# DSS0_DISPC_0_COMMON_M register map
Vendor: Texas Instruments
Peripheral module from a debugger description file (folder J7ES).
Registers are 32-bit, access per field, reset 0x0 unless marked. A register's access mark holds for its fields unless they carry their own. Offsets are as the file gives them; lines under a group give offsets from that group; [hi:lo] are bit positions; {n}, {i} and the like mark numbered series; 'fields as' and 'values as' point back to an identical list; <NAME> marks a mode.

## DSS0_DISPC_0_COMMON_M
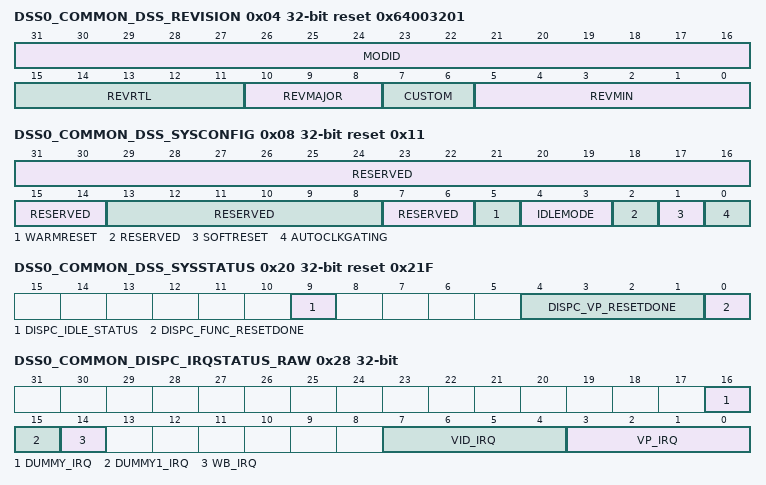
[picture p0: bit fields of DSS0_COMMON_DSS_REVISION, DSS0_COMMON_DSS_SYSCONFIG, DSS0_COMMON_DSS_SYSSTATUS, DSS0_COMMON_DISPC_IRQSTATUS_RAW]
0x04 DSS0_COMMON_DSS_REVISION ro reset 0x64003201 — This register contains the K3_DSS revision number
  [31:16] MODID — Module ID Field
  [15:11] REVRTL — RTL Revision
  [10:8] REVMAJOR — Major Revision
  [7:6] CUSTOM
  [5:0] REVMIN — Minor Revision
0x08 DSS0_COMMON_DSS_SYSCONFIG reset 0x11 — This register controls various parameters related to software reset and IP idle
  [31:14] RESERVED ro — Write 0's for future compatibility.
  [13:8] RESERVED ro — Write 0's for future compatibility.
  [7:6] RESERVED ro — Write 0's for future compatibility.
  [5] WARMRESET rw
  [4:3] IDLEMODE rw — Deprecated
  [2] RESERVED ro — Write 0's for future compatibility.
  [1] SOFTRESET rw — Software reset.
  [0] AUTOCLKGATING rw — Internal clock gating strategy
0x20 DSS0_COMMON_DSS_SYSSTATUS ro reset 0x21F — This register provides status information about the module, excluding the interrupt status information
  [9] DISPC_IDLE_STATUS — Idle status of DISPC
  [4:1] DISPC_VP_RESETDONE — Reset status of VP
  [0] DISPC_FUNC_RESETDONE — Reset status of DISPC Functional clock domain
0x28 DSS0_COMMON_DISPC_IRQSTATUS_RAW access not given — RAW Interrupt status. Raw status is set even if interrupt is not enabled. Write 1 to set the RAW status
  [16] DUMMY_IRQ — Dummy IRQ STATUS- Reserved for future use (access RW1S)
  [15] DUMMY1_IRQ — Dummy IRQ STATUS- Reserved for future use (access RW1S)
  [14] WB_IRQ — WB IRQ STATUS. (access RW1S)
  [7:4] VID_IRQ — VID IRQ STATUS. (access RW1S)
  [3:0] VP_IRQ — VP (access RW1S)
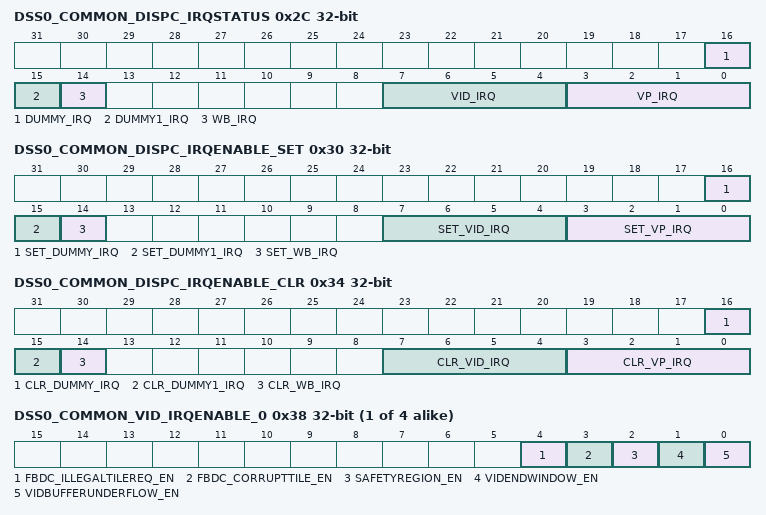
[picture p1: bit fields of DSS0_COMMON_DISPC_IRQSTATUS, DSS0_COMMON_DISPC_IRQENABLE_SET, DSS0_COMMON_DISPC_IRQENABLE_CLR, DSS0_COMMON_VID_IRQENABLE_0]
0x2C DSS0_COMMON_DISPC_IRQSTATUS access not given — Interrupt status. Enabled status, isn't set unless event is enabled. Write 1 to clear the status after interrupt has been serviced. RAW status also gets cleared, i.e. even if not enabled
  [16] DUMMY_IRQ — Dummy IRQ STATUS-Reserved for future use (access RW1C)
  [15] DUMMY1_IRQ — Dummy IRQ STATUS-Reserved for future use (access RW1C)
  [14] WB_IRQ — WB IRQ STATUS. (access RW1C)
  [7:4] VID_IRQ — VID IRQ STATUS. (access RW1C)
  [3:0] VP_IRQ — VP (access RW1C)
0x30 DSS0_COMMON_DISPC_IRQENABLE_SET access not given — SET Interrupt enable. Write 1 to set interrupt enable. Readout equal to corresponding _CLR register
  [16] SET_DUMMY_IRQ — Dummy IRQ (access RW1S)
  [15] SET_DUMMY1_IRQ — Dummy IRQ (access RW1S)
  [14] SET_WB_IRQ — WB IRQ, if WB pipeline is present (access RW1S)
  [7:4] SET_VID_IRQ — VID IRQ. (access RW1S)
  [3:0] SET_VP_IRQ — VP (access RW1S)
0x34 DSS0_COMMON_DISPC_IRQENABLE_CLR access not given — CLR Interrupt enable. Write 1 to clear interrupt enable
  [16] CLR_DUMMY_IRQ — Dummy IRQ (access RW1C)
  [15] CLR_DUMMY1_IRQ — Dummy IRQ (access RW1C)
  [14] CLR_WB_IRQ — WB IRQ, if WB pipeline is present (access RW1C)
  [7:4] CLR_VID_IRQ — VID IRQ.[0] -&gt; VID1, [1] -&gt; VIDL1, [2] -&gt; VID2, [3] -&gt; VIDL2 (access RW1C)
  [3:0] CLR_VP_IRQ — VP (access RW1C)
{0x38+4i} DSS0_COMMON_VID_IRQENABLE_{i} (i=0..3) — This register allows to mask/unmask the VID internal sources of interrupt, on an event-by-event basis.[0] -> VID1, [1] -> VIDL1, [2] -> VID2, [3] -> VIDL2
  [4] FBDC_ILLEGALTILEREQ_EN rw — FBDC IRQ, Illegal tile req detected
  [3] FBDC_CORRUPTTILE_EN rw — FBDC IRQ.
  [2] SAFETYREGION_EN rw — Safety Feature IRQ.
  [1] VIDENDWINDOW_EN rw — Video End Window.
  [0] VIDBUFFERUNDERFLOW_EN rw — Video DMA Buffer Underflow.
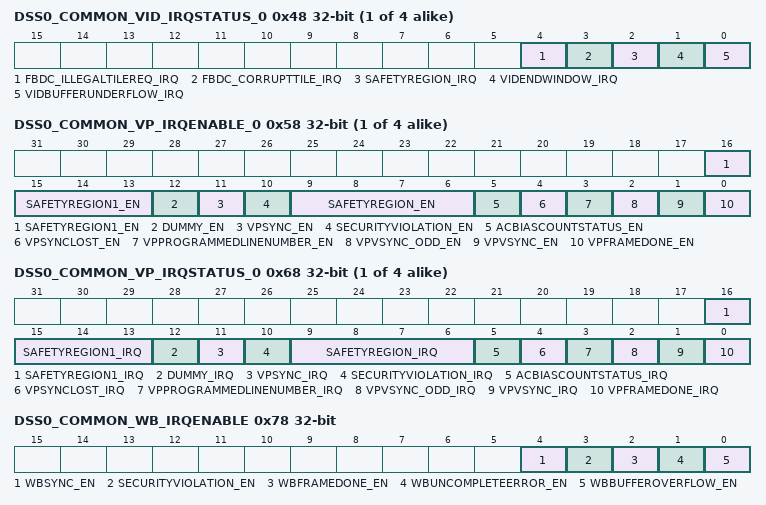
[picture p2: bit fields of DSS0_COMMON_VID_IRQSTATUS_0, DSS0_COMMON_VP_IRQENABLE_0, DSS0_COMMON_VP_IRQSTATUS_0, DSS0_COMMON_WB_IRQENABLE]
{0x48+4i} DSS0_COMMON_VID_IRQSTATUS_{i} access not given (i=0..3) — This register groups all the status of the VID internal events that generate an interrupt. Write 1 to a clear a bit field.[0] -> VID1, [1] -> VIDL1, [2] -> VID2, [3] -> VIDL2
  [4] FBDC_ILLEGALTILEREQ_IRQ — FBDC IRQ, Illegal tile req detected (access RW1C)
  [3] FBDC_CORRUPTTILE_IRQ — FBDC IRQ. (access RW1C)
  [2] SAFETYREGION_IRQ — Safety Feature IRQ. (access RW1C)
  [1] VIDENDWINDOW_IRQ — Video End Window. (access RW1C)
  [0] VIDBUFFERUNDERFLOW_IRQ — Video DMA Buffer Underflow. (access RW1C)
{0x58+4i} DSS0_COMMON_VP_IRQENABLE_{i} (i=0..3) — This register allows to mask/unmask the VP_{i} internal sources of interrupt, on an event-by-event basis
  [16:13] SAFETYREGION1_EN rw — Safety Feature IRQ.
  [12] DUMMY_EN rw — Dummy IRQ for future use
  [11] VPSYNC_EN rw — Go bit clear event
  [10] SECURITYVIOLATION_EN rw — Security Violation interrupt for OVR/VP.
  [9:6] SAFETYREGION_EN rw — Safety Feature IRQ.
  [5] ACBIASCOUNTSTATUS_EN rw — AC BIAS transition counter has decremented to zero
  [4] VPSYNCLOST_EN rw — Synchronization Lost for Video Port
  [3] VPPROGRAMMEDLINENUMBER_EN rw — Programmed Line Number.
  [2] VPVSYNC_ODD_EN rw — VSYNC for odd field from interlace mode only
  [1] VPVSYNC_EN rw — Vertical Synchronization for VP
  [0] VPFRAMEDONE_EN rw — Frame Done for Video Port.
{0x68+4i} DSS0_COMMON_VP_IRQSTATUS_{i} access not given (i=0..3) — This register groups all the status of the VP_{i} internal events that generate an interrupt. Write 1 to a given bit resets this bit
  [16:13] SAFETYREGION1_IRQ — Safety Feature IRQ. (access RW1C)
  [12] DUMMY_IRQ — Dummy IRQ for future use (access RW1C)
  [11] VPSYNC_IRQ — Go bit clear event (access RW1C)
  [10] SECURITYVIOLATION_IRQ — Security Violation IRQ. (access RW1C)
  [9:6] SAFETYREGION_IRQ — Safety Feature IRQ. (access RW1C)
  [5] ACBIASCOUNTSTATUS_IRQ — AC BIAS transition counter has decremented to zero (access RW1C)
  [4] VPSYNCLOST_IRQ — Synchronization Lost on VP output. (access RW1C)
  [3] VPPROGRAMMEDLINENUMBER_IRQ — Programmed Line Number. (access RW1C)
  [2] VPVSYNC_ODD_IRQ — VSYNC for odd field. (access RW1C)
  [1] VPVSYNC_IRQ — Vertical Synchronization for VP output. (access RW1C)
  [0] VPFRAMEDONE_IRQ — Frame Done for VP. (access RW1C)
0x78 DSS0_COMMON_WB_IRQENABLE — This register allows to mask/unmask the WB internal sources of interrupt, if WB pipeline is present, on an event-by-event basis
  [4] WBSYNC_EN rw — Write-back sync IRQ.
  [3] SECURITYVIOLATION_EN rw — Security Violation IRQ.
  [2] WBFRAMEDONE_EN rw — Write-back Frame Done
  [1] WBUNCOMPLETEERROR_EN rw — The write back buffer has been flushed before been fully drained.
  [0] WBBUFFEROVERFLOW_EN rw — Write-back DMA Buffer Overflow.
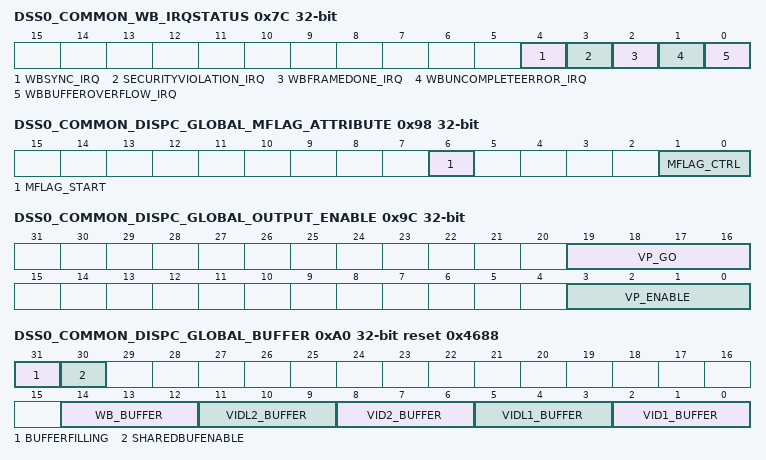
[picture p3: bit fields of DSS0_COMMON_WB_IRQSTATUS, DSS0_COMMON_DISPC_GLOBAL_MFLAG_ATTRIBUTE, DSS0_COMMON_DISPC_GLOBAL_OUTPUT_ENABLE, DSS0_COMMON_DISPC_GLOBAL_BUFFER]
0x7C DSS0_COMMON_WB_IRQSTATUS access not given — This register groups all the status of the WB internal events that generate an interrupt, if WB pipeline is present. Write 1 to a given bit resets this bit
  [4] WBSYNC_IRQ — Write-back sync IRQ. (access RW1C)
  [3] SECURITYVIOLATION_IRQ — Security Violation IRQ. (access RW1C)
  [2] WBFRAMEDONE_IRQ — Write-back Frame Done (access RW1C)
  [1] WBUNCOMPLETEERROR_IRQ — Write back DMA buffer is flushed before been completely drained. (access RW1C)
  [0] WBBUFFEROVERFLOW_IRQ — Write-back DMA Buffer Overflow The DMA buffer is full (access RW1C)
0x80 DSS0_COMMON_DISPC_IRQ_EOI_FUNC — End-Of-Interrupt register for FUNC interrupts, to be used if pulse interrupts are used The EOI register is used to re-trigger the pulse interrupt signal to ensure that any nested interrupt events are serviced. The software interrupt handler must write to the EOI register at the end of the current interrupt processing routine, so that new events can re-trigger the pulse interrupt signal again. For level interrupt signals the EOI register is not functional and must not be used.
  [0] EOI wo — Write 1 to acknowledge a pulse IRQ
0x84 DSS0_COMMON_DISPC_IRQ_EOI_SAFETY — End-Of-Interrupt register for SAFETY interrupts, to be used if pulse interrupts are used The EOI register is used to re-trigger the pulse interrupt signal to ensure that any nested interrupt events are serviced. The software interrupt handler must write to the EOI register at the end of the current interrupt processing routine, so that new events can re-trigger the pulse interrupt signal again. For level interrupt signals the EOI register is not functional and must not be used.
  [0] EOI wo — Write 1 to acknowledge a pulse IRQ
0x88 DSS0_COMMON_DISPC_IRQ_EOI_SECURITY — End-Of-Interrupt register for SECURITY interrupts, to be used if pulse interrupts are used The EOI register is used to re-trigger the pulse interrupt signal to ensure that any nested interrupt events are serviced. The software interrupt handler must write to the EOI register at the end of the current interrupt processing routine, so that new events can re-trigger the pulse interrupt signal again. For level interrupt signals the EOI register is not functional and must not be used.
  [0] EOI wo — Write 1 to acknowledge a pulse IRQ
0x90 DSS0_COMMON_DISPC_SECURE_DISABLE — Disable security settings throughout DSS IP. COMMON_1.DISPC_SECURE bits are honoured only if COMMON. =0
  [0] SECURE_DISABLE rw — Secure disable bit
0x98 DSS0_COMMON_DISPC_GLOBAL_MFLAG_ATTRIBUTE — MFLAG control register
  [6] MFLAG_START rw — MFLAG_START for DMA master port
  [1:0] MFLAG_CTRL rw — MFLAG_CTRL for DMA master port
0x9C DSS0_COMMON_DISPC_GLOBAL_OUTPUT_ENABLE — DISPC global output enable register. The ENABLE or GO bit for a particular output port is set when either the corresponding bit in this register is set or the corresponding bit within the sub-module is set. This register allows enabling multiple outputs synchronously [simultaneously], which is not possible if the ENABLE/GO bits are present only within the sub-module
  [19:16] VP_GO rw — Global GO Command for the VP
  [3:0] VP_ENABLE rw — Global VP
0xA0 DSS0_COMMON_DISPC_GLOBAL_BUFFER reset 0x4688 — The register configures the DMA buffers allocations to the pipelines for DMA
  [31] BUFFERFILLING rw — Controls if the DMA buffers are re-filled only when the LOW threshold is reached or if all DMA buffers are re-filled when at least one of them reaches the LOW threshold
  [30] SHAREDBUFENABLE rw — Enable Shared DMA Buffer feature
  [14:12] WB_BUFFER rw — WB DMA buffer allocation to one of the pipelines, if WB pipeline is present
  [11:9] VIDL2_BUFFER rw — VIDL2 DMA buffer allocation to one of the pipelines, if VIDL2 is present
  [8:6] VID2_BUFFER rw — VID2 DMA buffer allocation to one of the pipelines, if VID2 is present
  [5:3] VIDL1_BUFFER rw — VIDL1 DMA buffer allocation to one of the pipelines
  [2:0] VID1_BUFFER rw — VID1 DMA buffer allocation to one of the pipelines
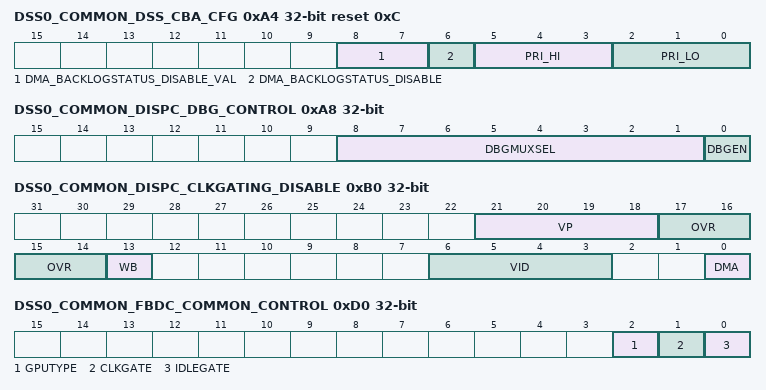
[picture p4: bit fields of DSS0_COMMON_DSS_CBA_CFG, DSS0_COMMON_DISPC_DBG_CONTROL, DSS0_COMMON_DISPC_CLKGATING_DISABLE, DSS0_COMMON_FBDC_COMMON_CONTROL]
0xA4 DSS0_COMMON_DSS_CBA_CFG reset 0xC — This register contains CBA specific config bits in DSS
  [8:7] DMA_BACKLOGSTATUS_DISABLE_VAL rw — IP Internal - Tie-off value on DMA_BACKLOGSTATUS pins when DMA Backlog Status reporting is disabled
  [6] DMA_BACKLOGSTATUS_DISABLE rw — IP Internal - Disable generation of DMA Backlog Status reporting to interconnect
  [5:3] PRI_HI rw — The value sent out on the PRI_HI bus from DSS to CBA Indicates the priority level for high-priority [MFLAG] transactions.
  [2:0] PRI_LO rw — The value sent out on the PRI_LO bus from DSS to CBA Indicates the priority level for normal [non-MFLAG] transactions.
0xA8 DSS0_COMMON_DISPC_DBG_CONTROL — DISPC debug status control register
  [8:1] DBGMUXSEL rw — Mux select for the debug status
  [0] DBGEN rw — Enable debug ports
0xAC DSS0_COMMON_DISPC_DBG_STATUS ro — DISPC debug status register
  [31:0] DBGOUT — Debug status
0xB0 DSS0_COMMON_DISPC_CLKGATING_DISABLE — Register to control clock gating at DISPC sub-module level
  [21:18] VP rw — Clock gating control for VP
  [17:14] OVR rw — Clock gating control for OVR
  [13] WB rw — Clock gating control for WB, if WB pipeline is present
  [6:3] VID rw — Clock gating control for VID.
  [0] DMA rw — Clock gating control for DMA
0xB8 DSS0_COMMON_FBDC_REVISION_1 ro — This register contains the FBDC Product Code
  [15:0] PRODUCTCODE — FBDC Product Code
0xBC DSS0_COMMON_FBDC_REVISION_2 ro — This register contains the FBDC Branch Code
  [15:0] BRANCHCODE — FBDC Branch Code
0xC0 DSS0_COMMON_FBDC_REVISION_3 ro — This register contains the FBDC Version Code
  [15:0] VERSIONCODE — FBDC Version Code
0xC4 DSS0_COMMON_FBDC_REVISION_4 ro — This register contains the FBDC Scalable Core Code
  [15:0] CORECODE — FBDC Scalable Core Code
0xC8 DSS0_COMMON_FBDC_REVISION_5 ro — This register contains the FBDC Configuration Code
  [15:0] CONFIGCODE — FBDC Configuration Code
0xCC DSS0_COMMON_FBDC_REVISION_6 ro — This register contains the FBDC Changelist Code
  [31:0] CHANGELISTCODE — FBDC Changelist Code
0xD0 DSS0_COMMON_FBDC_COMMON_CONTROL rw — This register contains the common control signals for FBDC
  [2] GPUTYPE — GPU Selection
  [1] CLKGATE — Reserved
  [0] IDLEGATE — Reserved
0xD4 DSS0_COMMON_FBDC_CONSTANT_COLOR_0 rw — Defines the Constant Color-0 value to be used for the FBDC
  [31:0] CONSTCOLOR
0xD8 DSS0_COMMON_FBDC_CONSTANT_COLOR_1 rw — Defines the Constant Color-1 value to be used for the FBDC
  [31:0] CONSTCOLOR
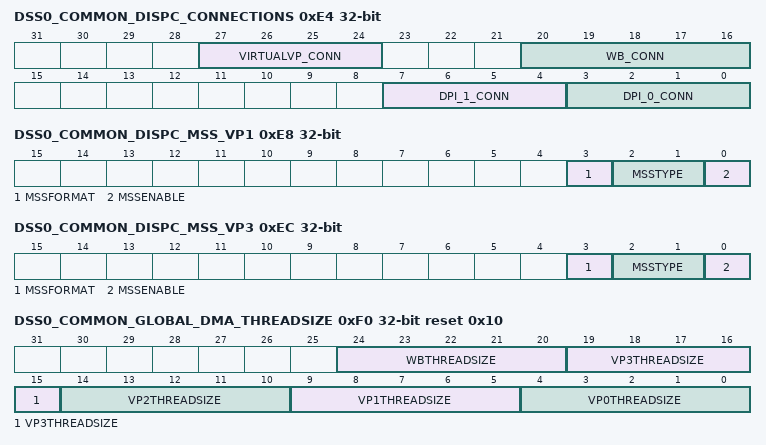
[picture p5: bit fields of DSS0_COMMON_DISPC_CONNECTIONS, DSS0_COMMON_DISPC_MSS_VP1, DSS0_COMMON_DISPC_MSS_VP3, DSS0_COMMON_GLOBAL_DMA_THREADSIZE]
0xE4 DSS0_COMMON_DISPC_CONNECTIONS rw — Connections of various sub-modules within DISPC, as well as some peripherals outside. One hot encoding
  [27:24] VIRTUALVP_CONN — Defines the connection to VIRTUAL_VP output
  [20:16] WB_CONN — Defines the connection to WB pipe
  [7:4] DPI_1_CONN — Defines the connection to DPI-1 output.
  [3:0] DPI_0_CONN — Defines the connection to DPI-0 output.
0xE8 DSS0_COMMON_DISPC_MSS_VP1 — This register controls the Merge_Split_Sync operation for VP1
  [3] MSSFORMAT rw — Merge Split format
  [2:1] MSSTYPE rw — Merge-Split-Sync operation type
  [0] MSSENABLE rw — Merge-Split-Sync operation Enable
0xEC DSS0_COMMON_DISPC_MSS_VP3 — This register controls the Merge_Split_Sync operation for VP3
  fields as DSS0_COMMON_DISPC_MSS_VP1
0xF0 DSS0_COMMON_GLOBAL_DMA_THREADSIZE reset 0x10 — This register configures the DMA buffer size allocated to the different threads - Shared memory feature
  [24:20] WBTHREADSIZE rw — Total DMA buffer size for all the pipelines connected to WB THREAD4.If the value programmed is n, then the allocated buffer size is 16KB*n.
  [5n+4:5n] VP{n}THREADSIZE rw (n=0..3) — Total DMA buffer size for all the pipelines connected to VP{n} THREAD{n}.If the value programmed is n, then the allocated buffer size is 16KB*n.
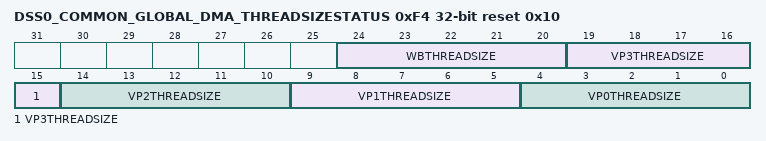
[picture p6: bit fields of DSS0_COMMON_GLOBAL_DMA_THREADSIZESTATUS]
0xF4 DSS0_COMMON_GLOBAL_DMA_THREADSIZESTATUS ro reset 0x10 — This register read the synchronized value of DMA buffer size allocated to the different threads - Shared memory feature
  [24:20] WBTHREADSIZE — Synchronized version of WB THREADSIZE.
  [5n+4:5n] VP{n}THREADSIZE (n=0..3) — Synchronized version of VP{n} THREADSIZE.
0xF8 DSS0_COMMON_GLOBAL_GOBITMODE — settings
  [0] MODE rw — Go bit
